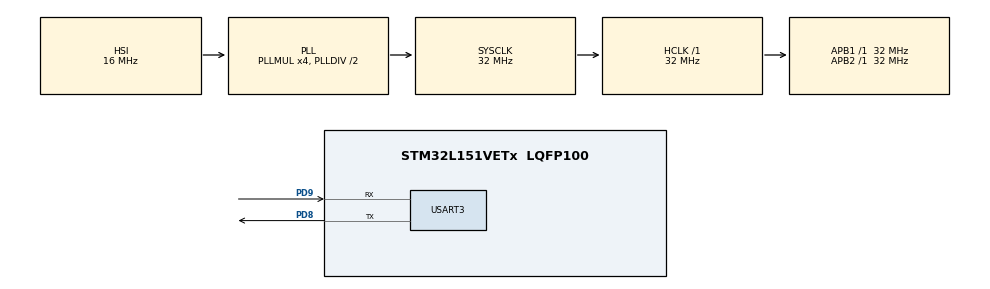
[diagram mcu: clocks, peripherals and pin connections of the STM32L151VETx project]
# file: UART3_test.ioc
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Mcu.Family=STM32L1
Mcu.Name=STM32L151VETx
Mcu.Package=LQFP100
NVIC.PriorityGroup=NVIC_PRIORITYGROUP_4
NVIC.TIM2_IRQn=true\:0\:0\:false\:false\:true\:false\:true
NVIC.TimeBase=TIM2_IRQn
NVIC.TimeBaseIP=TIM2
PC14-OSC32_IN.Mode=LSE-External-Oscillator
PC14-OSC32_IN.Signal=RCC_OSC32_IN
PC15-OSC32_OUT.Mode=LSE-External-Oscillator
PC15-OSC32_OUT.Signal=RCC_OSC32_OUT
PD8.Mode=Asynchronous
PD8.Signal=USART3_TX
PD9.Mode=Asynchronous
PD9.Signal=USART3_RX
PH0-OSC_IN.Mode=HSE-External-Oscillator
PH0-OSC_IN.Signal=RCC_OSC_IN
PH1-OSC_OUT.Mode=HSE-External-Oscillator
PH1-OSC_OUT.Signal=RCC_OSC_OUT
ProjectManager.HeapSize=0x200
ProjectManager.StackSize=0x400
ProjectManager.TargetToolchain=STM32CubeIDE
RCC.48MHZClocksFreq_Value=32000000
RCC.AHBFreq_Value=32000000
RCC.APB1Freq_Value=32000000
RCC.APB1TimFreq_Value=32000000
RCC.APB2Freq_Value=32000000
RCC.APB2TimFreq_Value=32000000
RCC.HCLKFreq_Value=32000000
RCC.HSE_VALUE=24000000
RCC.HSI_VALUE=16000000
RCC.MSI_VALUE=2097000
RCC.PLLMUL=RCC_PLL_MUL4
RCC.SYSCLKFreq_VALUE=32000000
RCC.SYSCLKSource=RCC_SYSCLKSOURCE_PLLCLK
RCC.VCOOutputFreq_Value=64000000
USART3.VirtualMode=VM_ASYNC
VP_SYS_VS_tim2.Mode=TIM2
board=custom

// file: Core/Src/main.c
/* USER CODE BEGIN Header */
/**
  ******************************************************************************
  * @file           : main.c
  * @brief          : Main program body
  ******************************************************************************
  * @attention
  *
  * <h2><center>&copy; Copyright (c) 2019 STMicroelectronics.
  * All rights reserved.</center></h2>
  *
  * This software component is licensed by ST under BSD 3-Clause license,
  * the "License"; You may not use this file except in compliance with the
  * License. You may obtain a copy of the License at:
  *                        opensource.org/licenses/BSD-3-Clause
  *
  ******************************************************************************
  */
/* USER CODE END Header */

#include "main.h"

/* USER CODE BEGIN Includes */
#include "stdio.h"
#include "SEGGER_RTT.h"
#include "elog.h"
/* USER CODE END Includes */

UART_HandleTypeDef huart3;

/* USER CODE BEGIN PV */
int nLoop=0;
/* USER CODE END PV */

void SystemClock_Config(void);
static void MX_GPIO_Init(void);
static void MX_USART3_UART_Init(void);

/* USER CODE BEGIN 0 */

static void test_elog(void);
/* USER CODE END 0 */

int main(void)
{
  /* USER CODE BEGIN 1 */
	int hello = 666;
  /* USER CODE END 1 */

  /* MCU Configuration--------------------------------------------------------*/

  /* Reset of all peripherals, Initializes the Flash interface and the Systick. */
  HAL_Init();

  /* Configure the system clock */
  SystemClock_Config();

  /* Initialize all configured peripherals */
  MX_GPIO_Init();
  MX_USART3_UART_Init();
  /* USER CODE BEGIN 2 */

	/* initialize EasyLogger */
	if (elog_init() == ELOG_NO_ERR)
	{
			/* set enabled format */
//			elog_set_fmt(ELOG_LVL_ASSERT, ELOG_FMT_ALL & ~ELOG_FMT_P_INFO);
//			elog_set_fmt(ELOG_LVL_ERROR, ELOG_FMT_ALL );
//			elog_set_fmt(ELOG_LVL_WARN, ELOG_FMT_LVL | ELOG_FMT_TAG | ELOG_FMT_TIME);
//			elog_set_fmt(ELOG_LVL_INFO, ELOG_FMT_TAG | ELOG_FMT_TIME);
//			elog_set_fmt(ELOG_LVL_DEBUG, ELOG_FMT_ALL & ~(ELOG_FMT_FUNC | ELOG_FMT_P_INFO));
//			elog_set_fmt(ELOG_LVL_VERBOSE, ELOG_FMT_ALL & ~(ELOG_FMT_FUNC | ELOG_FMT_P_INFO));

	        elog_set_fmt(ELOG_LVL_ASSERT, ELOG_FMT_ALL & ~ELOG_FMT_P_INFO);
	        elog_set_fmt(ELOG_LVL_ERROR, ELOG_FMT_LVL | ELOG_FMT_TAG | ELOG_FMT_TIME);
	        elog_set_fmt(ELOG_LVL_WARN, ELOG_FMT_LVL | ELOG_FMT_TAG | ELOG_FMT_TIME);
	        elog_set_fmt(ELOG_LVL_INFO, ELOG_FMT_LVL | ELOG_FMT_TAG | ELOG_FMT_TIME);
	        elog_set_fmt(ELOG_LVL_DEBUG, ELOG_FMT_ALL & ~(ELOG_FMT_FUNC | ELOG_FMT_P_INFO));
	        elog_set_fmt(ELOG_LVL_VERBOSE, ELOG_FMT_ALL & ~(ELOG_FMT_FUNC | ELOG_FMT_P_INFO));

			elog_set_text_color_enabled( true );

			elog_buf_enabled( false );

			/* start EasyLogger */
			elog_start();
	}

    elog_e("hw_fault", "hard fault on thread: %d",hello);

  /* USER CODE END 2 */

  /* Infinite loop */
  while (1)
  {

    /* USER CODE BEGIN 3 */
	  	  HAL_Delay(500);
	  	  nLoop++;
	  	  printf("nLoop == %d \n\r", nLoop);
	  	  printf("\n\r");
	  	  test_elog();

  }
  /* USER CODE END 3 */
}

void SystemClock_Config(void)
{
  RCC_OscInitTypeDef RCC_OscInitStruct = {0};
  RCC_ClkInitTypeDef RCC_ClkInitStruct = {0};

  /** Configure the main internal regulator output voltage
  */
  __HAL_PWR_VOLTAGESCALING_CONFIG(PWR_REGULATOR_VOLTAGE_SCALE1);
  /** Initializes the CPU, AHB and APB busses clocks
  */
  RCC_OscInitStruct.OscillatorType = RCC_OSCILLATORTYPE_HSI;
  RCC_OscInitStruct.HSIState = RCC_HSI_ON;
  RCC_OscInitStruct.HSICalibrationValue = RCC_HSICALIBRATION_DEFAULT;
  RCC_OscInitStruct.PLL.PLLState = RCC_PLL_ON;
  RCC_OscInitStruct.PLL.PLLSource = RCC_PLLSOURCE_HSI;
  RCC_OscInitStruct.PLL.PLLMUL = RCC_PLL_MUL4;
  RCC_OscInitStruct.PLL.PLLDIV = RCC_PLL_DIV2;
  if (HAL_RCC_OscConfig(&RCC_OscInitStruct) != HAL_OK)
  {
    Error_Handler();
  }
  /** Initializes the CPU, AHB and APB busses clocks
  */
  RCC_ClkInitStruct.ClockType = RCC_CLOCKTYPE_HCLK|RCC_CLOCKTYPE_SYSCLK
                              |RCC_CLOCKTYPE_PCLK1|RCC_CLOCKTYPE_PCLK2;
  RCC_ClkInitStruct.SYSCLKSource = RCC_SYSCLKSOURCE_PLLCLK;
  RCC_ClkInitStruct.AHBCLKDivider = RCC_SYSCLK_DIV1;
  RCC_ClkInitStruct.APB1CLKDivider = RCC_HCLK_DIV1;
  RCC_ClkInitStruct.APB2CLKDivider = RCC_HCLK_DIV1;

  if (HAL_RCC_ClockConfig(&RCC_ClkInitStruct, FLASH_LATENCY_1) != HAL_OK)
  {
    Error_Handler();
  }
}

static void MX_USART3_UART_Init(void)
{

  huart3.Instance = USART3;
  huart3.Init.BaudRate = 115200;
  huart3.Init.WordLength = UART_WORDLENGTH_8B;
  huart3.Init.StopBits = UART_STOPBITS_1;
  huart3.Init.Parity = UART_PARITY_NONE;
  huart3.Init.Mode = UART_MODE_TX_RX;
  huart3.Init.HwFlowCtl = UART_HWCONTROL_NONE;
  huart3.Init.OverSampling = UART_OVERSAMPLING_16;
  if (HAL_UART_Init(&huart3) != HAL_OK)
  {
    Error_Handler();
  }

}

static void MX_GPIO_Init(void)
{

  /* GPIO Ports Clock Enable */
  __HAL_RCC_GPIOC_CLK_ENABLE();
  __HAL_RCC_GPIOH_CLK_ENABLE();
  __HAL_RCC_GPIOD_CLK_ENABLE();

}

/* USER CODE BEGIN 4 */
//int __io_putchar(int ch,FILE *f)
//{
////    uint8_t c[1];
////    c[0] = ch & 0x00FF;
//	SEGGER_RTT_Write( 0, &ch, 1);
//
////    HAL_UART_Transmit(&huart3, &*c, 1, 10);
//    return ch;
//}
/**
 * EasyLogger demo
 */
void test_elog(void) {
    /* test log output for all level */
    log_a("Hello EasyLogger!");
    log_e("Hello EasyLogger!");
    log_w("Hello EasyLogger!");
    log_i("Hello EasyLogger!");
    log_d("Hello EasyLogger!");
    log_v("Hello EasyLogger!");
//    elog_raw("Hello EasyLogger!");
}
//int _write(int file, char *ptr, int len)
//{
//    int DataIdx;
//    for (DataIdx = 0; DataIdx < len; DataIdx++)
//    {
//        __io_putchar(*ptr++);
//    }
//    return len;
//}
/* USER CODE END 4 */

void HAL_TIM_PeriodElapsedCallback(TIM_HandleTypeDef *htim)
{
  if (htim->Instance == TIM2) {
    HAL_IncTick();
  }
}

void Error_Handler(void)
{
}

/************************ (C) COPYRIGHT STMicroelectronics *****END OF FILE****/
